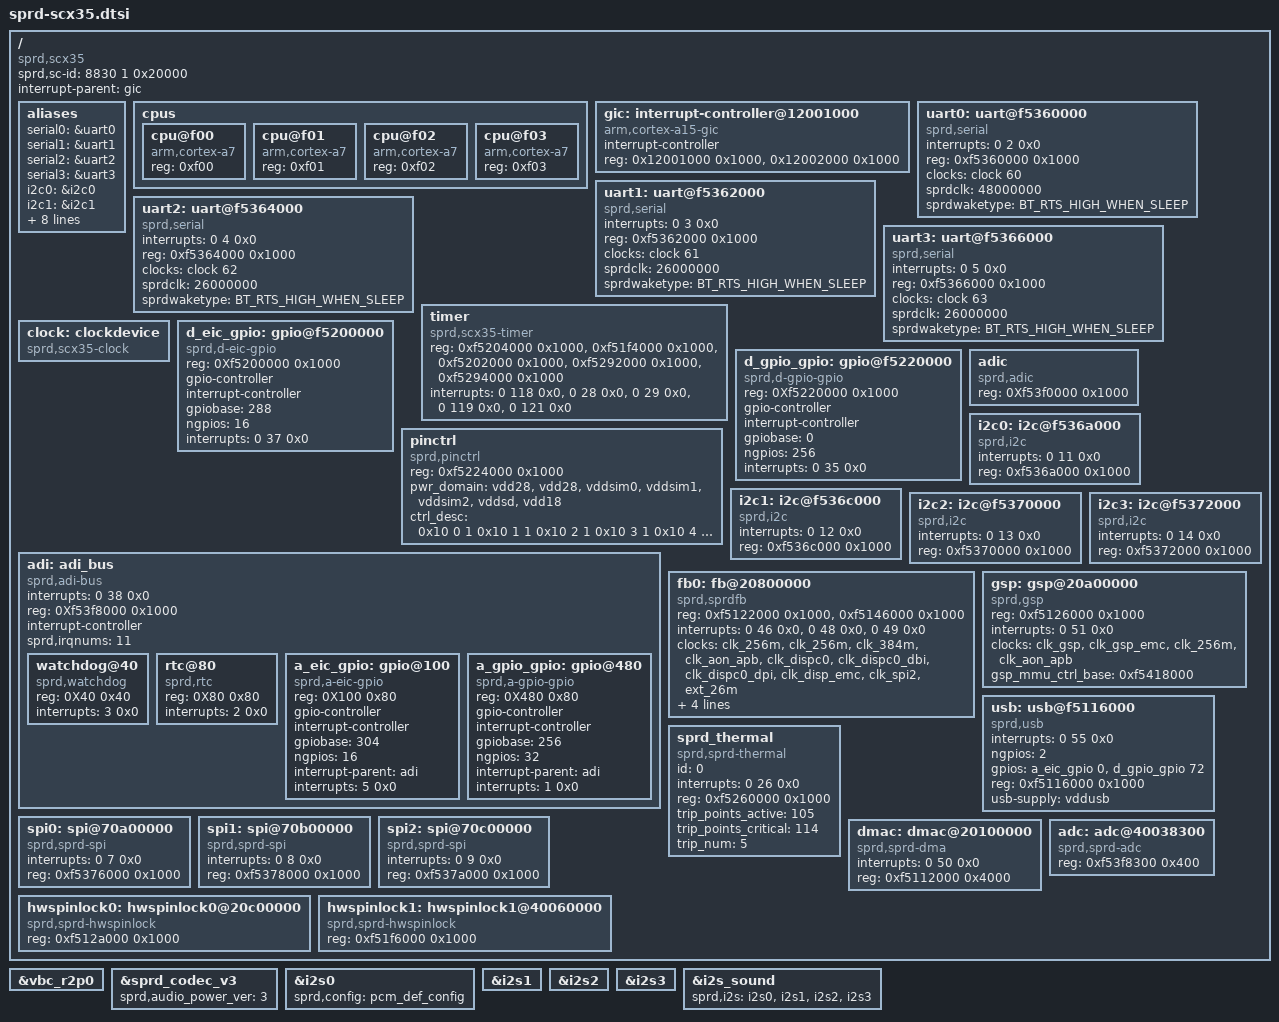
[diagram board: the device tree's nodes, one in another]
/*
* Copyright (C) 2013 Spreadtrum Communication Incorporated
*		http://www.spreadtrum.com/
*
* This program is free software; you can redistribute it and/or modify
* it under the terms of the GNU General Public License version 2 as
* published by the Free Software Foundation.
*/
/include/ "skeleton.dtsi"
/include/ "scx30g-clocks.dtsi"
/include/ "scx30g-regulators.dtsi"
/include/ "sprd-sound.dtsi"

/ {
	compatible = "sprd,scx35";
	sprd,sc-id = <8830 1 0x20000>;
	#address-cells = <1>;
	#size-cells = <1>;
	interrupt-parent = <&gic>;

	aliases {
		serial0 = &uart0;
		serial1 = &uart1;
		serial2 = &uart2;
		serial3 = &uart3;
		i2c0 = &i2c0;
		i2c1 = &i2c1;
		i2c2 = &i2c2;
		i2c3 = &i2c3;
		lcd0 = &fb0;
		spi0 = &spi0;
		spi1 = &spi1;
		spi2 = &spi2;
		hwspinlock0 = &hwspinlock0;
		hwspinlock1 = &hwspinlock1;
	};

	cpus {
		#address-cells = <1>;
		#size-cells = <0>;

		cpu@f00 {
			device_type = "cpu";
			compatible = "arm,cortex-a7";
			reg = <0xf00>;
		};

		cpu@f01 {
			device_type = "cpu";
			compatible = "arm,cortex-a7";
			reg = <0xf01>;
		};

		cpu@f02 {
			device_type = "cpu";
			compatible = "arm,cortex-a7";
			reg = <0xf02>;
		};

		cpu@f03 {
			device_type = "cpu";
			compatible = "arm,cortex-a7";
			reg = <0xf03>;
		};
	};

    gic: interrupt-controller@12001000 {
        compatible = "arm,cortex-a15-gic", "arm,cortex-a9-gic";
        #interrupt-cells = <3>;
        #address-cells = <0>;
        interrupt-controller;
        reg = <0x12001000 0x1000>,
              <0x12002000 0x1000>;
    };

	 uart0: uart@f5360000{
		 compatible  = "sprd,serial";
		 interrupts = <0 2 0x0>;
		 reg = <0xf5360000 0x1000>;
		 clock-names = "clk_uart0";
		 clocks = <&clock 60>;
		 sprdclk = <48000000>;
		 sprdwaketype = "BT_RTS_HIGH_WHEN_SLEEP";
	 };
	 uart1: uart@f5362000{
		 compatible  = "sprd,serial";
		 interrupts = <0 3 0x0>;
		 reg = <0xf5362000 0x1000>;
		 clock-names = "clk_uart1";
		 clocks = <&clock 61>;
		 sprdclk = <26000000>;
		 sprdwaketype = "BT_RTS_HIGH_WHEN_SLEEP";
	 };
	 uart2: uart@f5364000{
		 compatible  = "sprd,serial";
		 interrupts = <0 4 0x0>;
		 reg = <0xf5364000 0x1000>;
		 clock-names = "clk_uart2";
		 clocks = <&clock 62>;
		 sprdclk = <26000000>;
		 sprdwaketype = "BT_RTS_HIGH_WHEN_SLEEP";
	 };
	 uart3: uart@f5366000{
		 compatible  = "sprd,serial";
		 interrupts = <0 5 0x0>;
		 reg = <0xf5366000 0x1000>;
		 clock-names = "clk_uart3";
		 clocks = <&clock 63>;
		 sprdclk = <26000000>;
		 sprdwaketype = "BT_RTS_HIGH_WHEN_SLEEP";
	 };

	 timer{
		 compatible  = "sprd,scx35-timer";
		 reg = <0xf5204000 0x1000>,
			 <0xf51f4000 0x1000>,
			 <0xf5202000 0x1000>,
			 <0xf5292000 0x1000>,
			 <0xf5294000 0x1000>;
		 interrupts = <0 118 0x0>,
					<0 28 0x0>,
					<0 29 0x0>,
					<0 119 0x0>,
					<0 121 0x0>;
	 };
	 clock: clockdevice{
		 compatible = "sprd,scx35-clock";
		#clock-cells = <1>;
	 };
	 d_eic_gpio: gpio@f5200000{
		 compatible = "sprd,d-eic-gpio";
		 reg = <0Xf5200000 0x1000>;
		 gpio-controller;
		 interrupt-controller;
		 #interrupt-cells = <2>;
		 #gpio-cells = <2>;
		 gpiobase = <288>;
		 ngpios = <16>;
		 interrupts = <0 37 0x0>;
	 };
	 d_gpio_gpio: gpio@f5220000{
		 compatible = "sprd,d-gpio-gpio";
		 reg = <0Xf5220000 0x1000>;
		 gpio-controller;
		 interrupt-controller;
		 #interrupt-cells = <2>;
		 #gpio-cells = <2>;
		 gpiobase = <0>;
		 ngpios = <256>;
		 interrupts = <0 35 0x0>;
	 };
	adic:adic{
		compatible = "sprd,adic";
		reg = <0Xf53f0000 0x1000>;
	};
	pinctrl{
		compatible = "sprd,pinctrl";
		reg = <0xf5224000 0x1000>;
		pwr_domain = "vdd28",
		"vdd28",
		"vddsim0",
		"vddsim1",
		"vddsim2",
		"vddsd",
		"vdd18";
		ctrl_desc = <0x10 0 1
				0x10 1 1
				0x10 2 1
				0x10 3 1
				0x10 4 1
				0x10 5 1
				0x10 6 1>;
	};
	 adi: adi_bus{
		 compatible = "sprd,adi-bus";
		 interrupts = <0 38 0x0>;
		 reg = <0Xf53f8000 0x1000>;
		 interrupt-controller;
		 sprd,irqnums = <11>;
		 #interrupt-cells = <2>;
		 #address-cells = <1>;
		 #size-cells = <1>;
		 ranges = <0X40 0Xf53f8040 0x40>,
				  <0X80 0Xf53f8080 0x80>,
		 		  <0X100 0Xf53f8100 0x80>,
		 		  <0X480 0Xf53f8480 0x80>;
		 watchdog@40{
		 	compatible = "sprd,watchdog";
		 	reg = <0X40 0x40>;
		 	interrupts = <3 0x0>;
		 };
		 rtc@80{
		 	compatible = "sprd,rtc";
		 	reg = <0X80 0x80>;
		 	interrupts = <2 0x0>;
		};
		 a_eic_gpio: gpio@100{
			 compatible = "sprd,a-eic-gpio";
			 reg = <0X100 0x80>; /* adi reg */
			 gpio-controller;
			 interrupt-controller;
			 #interrupt-cells = <2>;
			 #gpio-cells = <2>;
			 gpiobase = <304>;
			 ngpios = <16>;
			 interrupt-parent = <&adi>;
			 interrupts = <5 0x0>; /* ext irq 5 */
		 };
		 a_gpio_gpio: gpio@480{
			 compatible = "sprd,a-gpio-gpio";
			 reg = <0X480 0x80>; /* adi reg */
			 gpio-controller;
			 interrupt-controller;
			 #interrupt-cells = <2>;
			 #gpio-cells = <2>;
			 gpiobase = <256>;
			 ngpios = <32>;
			 interrupt-parent = <&adi>;
			 interrupts = <1 0x0>; /* ext irq 1 */
		 };
	 };

	 i2c0: i2c@f536a000{
		 compatible  = "sprd,i2c";
		 interrupts = <0 11 0x0>;
		 reg = <0xf536a000 0x1000>;
		 #address-cells = <1>;
		 #size-cells = <0>;
	 };
	 i2c1: i2c@f536c000{
		 compatible  = "sprd,i2c";
		 interrupts = <0 12 0x0>;
		 reg = <0xf536c000 0x1000>;
		 #address-cells = <1>;
		 #size-cells = <0>;
	 };
	 i2c2: i2c@f5370000{
		 compatible  = "sprd,i2c";
		 interrupts = <0 13 0x0>;
		 reg = <0xf5370000 0x1000>;
		 #address-cells = <1>;
	 };
	 i2c3: i2c@f5372000{
		 compatible  = "sprd,i2c";
		 interrupts = <0 14 0x0>;
		 reg = <0xf5372000 0x1000>;
		 #address-cells = <1>;
		 #size-cells = <0>;
	 };

	fb0: fb@20800000 {
		compatible = "sprd,sprdfb";
		reg = <0xf5122000 0x1000>,<0xf5146000 0x1000>;
		interrupts = <0 46 0x0>,<0 48 0x0>, <0 49 0x0>;
		clock-names = "dispc_clk_parent", "dispc_dbi_clk_parent", "dispc_dpi_clk_parent", "dispc_emc_clk_parent", "dispc_clk", "dispc_dbi_clk", "dispc_dpi_clk", "dispc_emc_clk", "fb_spi_clock", "fb_spi_clock_parent";
		clocks = <&clk_256m>, <&clk_256m>, <&clk_384m>, <&clk_aon_apb>, <&clk_dispc0>, <&clk_dispc0_dbi>, <&clk_dispc0_dpi>, <&clk_disp_emc>, <&clk_spi2>, <&ext_26m>;
		clock-src = <256000000 256000000 384000000>;
		dpi_clk_div = <7>;
		sprd,fb_use_reservemem;
		sprd,fb_mem = <0x9f300000 0x600000>;
	};

	gsp:gsp@20a00000 {
		compatible = "sprd,gsp";
		reg = <0xf5126000 0x1000>;
		interrupts = <0 51 0x0>;
		clock-names = "clk_gsp", "clk_gsp_emc", "clk_gsp_parent", "clk_aon_apb";
		clocks = <&clk_gsp>, <&clk_gsp_emc>, <&clk_256m>, <&clk_aon_apb>;
		gsp_mmu_ctrl_base = <0xf5418000>;
	};

	usb: usb@f5116000{
		 compatible  = "sprd,usb";
		 interrupts = <0 55 0x0>;
		ngpios = <2>;
		gpios = <&a_eic_gpio 0 0>,<&d_gpio_gpio 72 0>;
		 reg = <0xf5116000 0x1000>;
                 usb-supply = <&vddusb>;
		 #address-cells = <1>;
		 #size-cells = <0>;
	 };
	sprd_thermal {
		compatible = "sprd,sprd-thermal";
		id = <0>;
		interrupts = <0 26 0x0>;
		reg = <0xf5260000 0x1000>;
		trip_points_active = <105>;
		trip_points_critical = <114>;
		trip_num = <5>;
	};

	 spi0: spi@70a00000{
		 compatible  = "sprd,sprd-spi";
		 interrupts = <0 7 0x0>;
		 reg = <0xf5376000 0x1000>;
		 clock-names = "clk_spi0";
		 #address-cells = <1>;
		 #size-cells = <0>;
	 };
	 spi1: spi@70b00000{
		 compatible  = "sprd,sprd-spi";
		 interrupts = <0 8 0x0>;
		 reg = <0xf5378000 0x1000>;
		 clock-names = "clk_spi1";
		 #address-cells = <1>;
		 #size-cells = <0>;
	 };
	 spi2: spi@70c00000{
		 compatible  = "sprd,sprd-spi";
		 interrupts = <0 9 0x0>;
		 reg = <0xf537a000 0x1000>;
		 clock-names = "clk_spi2";
		 #address-cells = <1>;
		 #size-cells = <0>;
	 };
	 dmac: dmac@20100000{
		 compatible  = "sprd,sprd-dma";
		 interrupts = <0 50 0x0>;
		 reg = <0xf5112000 0x4000>;
	 };
	 adc: adc@40038300{
		 compatible  = "sprd,sprd-adc";
		 reg = <0xf53f8300 0x400>;
	 };
	 hwspinlock0: hwspinlock0@20c00000{
		 compatible  = "sprd,sprd-hwspinlock";
		 reg = <0xf512a000 0x1000>;
	 };
	 hwspinlock1: hwspinlock1@40060000{
		 compatible  = "sprd,sprd-hwspinlock";
		 reg = <0xf51f6000 0x1000>;
	 };
};

&vbc_r2p0 {
	status = "okay";
};

&sprd_codec_v3 {
	status = "okay";
	sprd,audio_power_ver = <3>;
};

&i2s0 {
        sprd,config = <&pcm_def_config>;
	status = "okay";
};

&i2s1 {
	status = "okay";
};

&i2s2 {
	status = "okay";
};

&i2s3 {
	status = "okay";
};

&i2s_sound {
	sprd,i2s = <&i2s0>, <&i2s1>, <&i2s2>, <&i2s3>;
};
